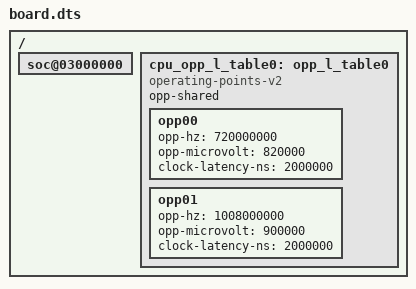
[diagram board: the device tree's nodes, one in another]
/*
 * Allwinner Technology CO., Ltd. sun8iw18p1 soc board.
 *
 * soc board support.
 */

/dts-v1/;

#include "sun8iw18p1.dtsi"

/{

	soc@03000000 {

	};

	cpu_opp_l_table0: opp_l_table0 {
		compatible = "operating-points-v2";
		opp-shared;

		opp00 {
			opp-hz = /bits/ 64 <720000000>;
			opp-microvolt = <820000>;
			clock-latency-ns = <2000000>;
		};

		opp01 {
			opp-hz = /bits/ 64 <1008000000>;
			opp-microvolt = <900000>;
			clock-latency-ns = <2000000>;
		};
	};
};
